# VPAC0_COMMON_0_PAR_VPAC_VISS0_S_VBUSP_VISS_FCP2_EE_VBUSP_FLEXEE register map
Vendor: Texas Instruments
Peripheral module from a debugger description file (folder J721S2).
Registers are 32-bit, read-write, reset 0x0 unless marked. A register's access mark holds for its fields unless they carry their own. Offsets are as the file gives them; lines under a group give offsets from that group; [hi:lo] are bit positions; {n}, {i} and the like mark numbered series; 'fields as' and 'values as' point back to an identical list; <NAME> marks a mode.

## VPAC0_COMMON_0_PAR_VPAC_VISS0_S_VBUSP_VISS_FCP2_EE_VBUSP_FLEXEE
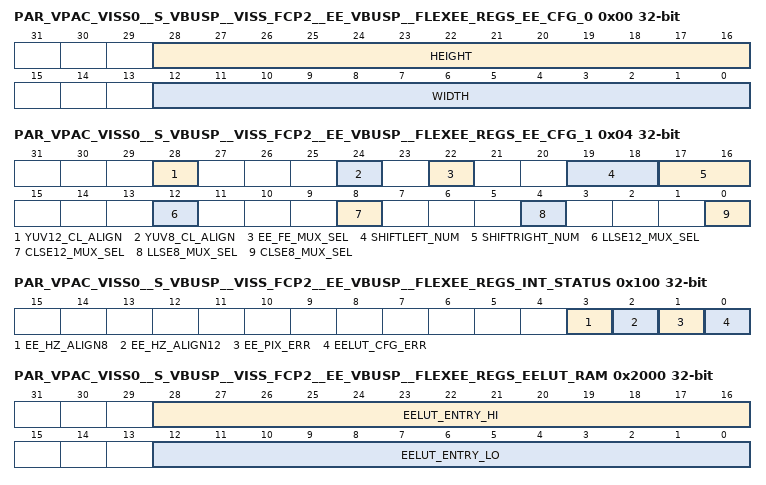
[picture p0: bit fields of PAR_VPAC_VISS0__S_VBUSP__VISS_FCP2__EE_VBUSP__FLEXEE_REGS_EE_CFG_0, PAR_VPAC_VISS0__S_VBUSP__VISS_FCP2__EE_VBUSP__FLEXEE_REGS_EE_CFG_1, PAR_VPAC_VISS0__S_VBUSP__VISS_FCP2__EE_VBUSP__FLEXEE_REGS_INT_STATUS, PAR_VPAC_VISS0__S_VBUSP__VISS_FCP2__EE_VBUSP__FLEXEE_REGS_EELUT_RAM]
0x00 PAR_VPAC_VISS0__S_VBUSP__VISS_FCP2__EE_VBUSP__FLEXEE_REGS_EE_CFG_0
  [28:16] HEIGHT — Height of the input image
  [12:0] WIDTH — Width of the input image
0x04 PAR_VPAC_VISS0__S_VBUSP__VISS_FCP2__EE_VBUSP__FLEXEE_REGS_EE_CFG_1
  [28] YUV12_CL_ALIGN — Enables the alignment of the Chroma and Luma for the yuv12 stream. The aligner can align the Chroma and Luma +-19 pixel clocks. 1: Enable alignment. 0: Pass Chroma and Luma as they arrive.
  [24] YUV8_CL_ALIGN — Enables the alignment of the Chroma and Luma for the yuv8 stream. The aligner can align the Chroma and Luma +-19 pixel clocks. 1: Enable alignment. 0: Pass Chroma and Luma as they arrive.
  [22] EE_FE_MUX_SEL — Selects which data stream to pass through the EE block. 0: Selects the yuv12 stream. 1: selects the yuv8 stream.
  [19:18] SHIFTLEFT_NUM — Sects the amount to shift left the incoming pixel to the EE block. 0: No Shift. 1: Shift by 2. 2: Shift by 4. 3: Reserved for future expansion.
  [17:16] SHIFTRIGHT_NUM — Sects the amount to shift right the outgoing pixel from the EE block. 0: No Shift. 1: Shift by 2. 2: Shift by 4. 3: Reserved for future expansion.
  [12] LLSE12_MUX_SEL — Selects Luma stream for the yuv12 output. 0: Bypass EE block. 1: Use EE Luma Output.
  [8] CLSE12_MUX_SEL — Selects Chroma stream for the yuv12 output. 0: Bypass EE block. 1: Use EE Chroma Output.
  [4] LLSE8_MUX_SEL — Selects Luma stream for the yuv8 output. 0: Bypass EE block. 1: Use EE Luma Output.
  [0] CLSE8_MUX_SEL — Selects Chroma stream for the yuv8 output. 0: Bypass EE block. 1: Use EE Chroma Output.
0x08 PAR_VPAC_VISS0__S_VBUSP__VISS_FCP2__EE_VBUSP__FLEXEE_REGS_EE_ENABLE
  [0] YEE_ENABLE — The EE Enable register control the internal bypass of the EE block.
0x0C PAR_VPAC_VISS0__S_VBUSP__VISS_FCP2__EE_VBUSP__FLEXEE_REGS_YEE_SHIFT
  [5:0] YEE_SHIFT — The down shift length of high pass filter (HPF) in edge enhancer takes the output of the 5x5 HPF and shifts it by the selected amount. Only values 0-31 are valid.
{0x10+0x10*i} PAR_VPAC_VISS0__S_VBUSP__VISS_FCP2__EE_VBUSP__FLEXEE_REGS_YEE_COEF_R{i}_C0 (i=0..2)
  [9:0] YEE_COEF_R{i}_C0 — The Multiplier coefficient for the given row/col is used in the HPF and can range from -512 to 511.
{0x14+0x10*i} PAR_VPAC_VISS0__S_VBUSP__VISS_FCP2__EE_VBUSP__FLEXEE_REGS_YEE_COEF_R{i}_C1 (i=0..2)
  [9:0] YEE_COEF_R{i}_C1 — The Multiplier coefficient for the given row/col is used in the HPF and can range from -512 to 511.
{0x18+0x10*i} PAR_VPAC_VISS0__S_VBUSP__VISS_FCP2__EE_VBUSP__FLEXEE_REGS_YEE_COEF_R{i}_C2 (i=0..2)
  [9:0] YEE_COEF_R{i}_C2 — The Multiplier coefficient for the given row/col is used in the HPF and can range from -512 to 511.
0x40 PAR_VPAC_VISS0__S_VBUSP__VISS_FCP2__EE_VBUSP__FLEXEE_REGS_YEE_E_THR
  [9:0] YEE_E_THR — The yee_e_thr is the Shrink Threshold before the LUT, scaled by 16x.
0x44 PAR_VPAC_VISS0__S_VBUSP__VISS_FCP2__EE_VBUSP__FLEXEE_REGS_YEE_MERGESEL
  [0] YEE_MERGESEL — The yee_mergesel selects either the sum of the LUT and edge sharpener output of the max of the absolute values from both. 0: selects the SUM. 1: elects the absolute value max.
0x48 PAR_VPAC_VISS0__S_VBUSP__VISS_FCP2__EE_VBUSP__FLEXEE_REGS_YES_E_HAL
  [0] YES_E_HAL — The yes_e_hal selects whether the 3x3 gradients is used to clip the target pixel. 0: Halo reduction off. 1: Halo reduction on.
0x4C PAR_VPAC_VISS0__S_VBUSP__VISS_FCP2__EE_VBUSP__FLEXEE_REGS_YES_G_GAIN
  [7:0] YES_G_GAIN — Sets the Gradient Gain value
0x50 PAR_VPAC_VISS0__S_VBUSP__VISS_FCP2__EE_VBUSP__FLEXEE_REGS_YES_E_GAIN
  [11:0] YES_E_GAIN — Sets the Edge sharpener Band-pass filter gain
0x54 PAR_VPAC_VISS0__S_VBUSP__VISS_FCP2__EE_VBUSP__FLEXEE_REGS_YES_E_THR1
  [15:0] YES_E_THR1 — Sets the Edge sharpener HPF value lower limit shrink threshold
0x58 PAR_VPAC_VISS0__S_VBUSP__VISS_FCP2__EE_VBUSP__FLEXEE_REGS_YES_E_THR2
  [9:0] YES_E_THR2 — Sets the Edge sharpener HPF value upper limit (after 6 bit right shift) clip threshold
0x5C PAR_VPAC_VISS0__S_VBUSP__VISS_FCP2__EE_VBUSP__FLEXEE_REGS_YES_G_OFT
  [9:0] YES_G_OFT — Sets the Edge sharpener offset value on gradient
0x100 PAR_VPAC_VISS0__S_VBUSP__VISS_FCP2__EE_VBUSP__FLEXEE_REGS_INT_STATUS access not given
  [3] EE_HZ_ALIGN8 — status/clear for EE horizontal aligner yuv8 overflow error indicates that the luma and chroma line starts were not within hardware synchronization limits. Write 1 to clear, write 0 has no effect. (access R/W1TC)
  [2] EE_HZ_ALIGN12 — status/clear for EE horizontal aligner yuv12 overflow error indicates that the luma and chroma line starts were not within hardware synchronization limits. Write 1 to clear, write 0 has no effect. (access R/W1TC)
  [1] EE_PIX_ERR — status/clear for error on line array, set when software accesses EE pixel array during active frame causing potential frame corruption. Write 1 to clear, write 0 has no effect. (access R/W1TC)
  [0] EELUT_CFG_ERR — status/clear for error on EE LUT cfg, set when software accesses EE LUT during active frame causing potential frame corruption. Write 1 to clear, write 0 has no effect. (access R/W1TC)
0x1008 PAR_VPAC_VISS0__S_VBUSP__VISS_FCP2__EE_VBUSP__FLEXEE_REGS_LINE_SEL
  [2:0] LINE_SELECTOR — Selects which line is read or written from the line memory array. The current line is updated at Start-Of-Line, so if the memory is read during a line that is being written, the data for the current_line will contain the new data for this current_line as well as old data from current_line - 5 that has not been overridden yet. If the current_line is the first few lines of a frame, the other lines will be from the end of the previous frame. '0' = current line written, '1' = current line - 1, 2 = current line - 2, 3 = current line - 3, 4 = current side band line. 5 = current side band line - 1.
0x2000 PAR_VPAC_VISS0__S_VBUSP__VISS_FCP2__EE_VBUSP__FLEXEE_REGS_EELUT_RAM
  [28:16] EELUT_ENTRY_HI — The lower EE LUT entry n+1.
  [12:0] EELUT_ENTRY_LO — The lower EE LUT entry n+0.
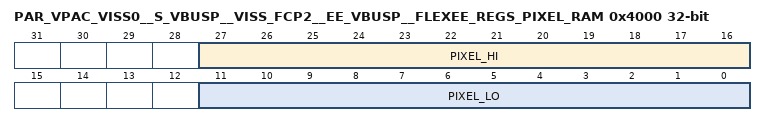
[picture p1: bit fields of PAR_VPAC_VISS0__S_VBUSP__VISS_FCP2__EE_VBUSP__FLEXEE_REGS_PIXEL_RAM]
0x4000 PAR_VPAC_VISS0__S_VBUSP__VISS_FCP2__EE_VBUSP__FLEXEE_REGS_PIXEL_RAM
  [27:16] PIXEL_HI — The 12 bit pixel data for the selected line upper pixel 'n+1'
  [11:0] PIXEL_LO — The 12 bit pixel data for the selected line lower pixel 'n'
